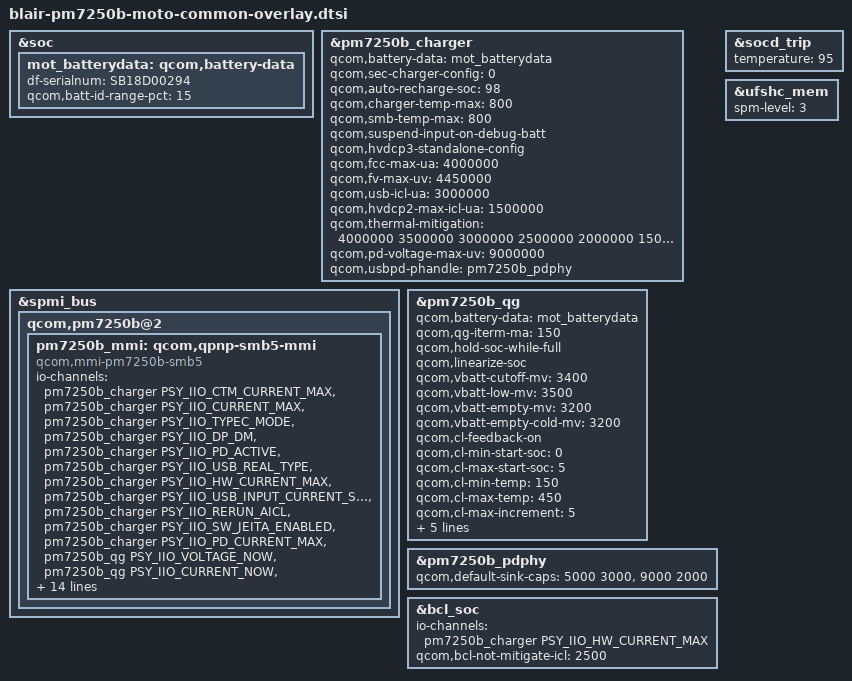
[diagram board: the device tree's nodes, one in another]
/* Copyright (c) 2020, The Linux Foundation. All rights reserved.
 *
 * This program is free software; you can redistribute it and/or modify
 * it under the terms of the GNU General Public License version 2 and
 * only version 2 as published by the Free Software Foundation.
 *
 * This program is distributed in the hope that it will be useful,
 * but WITHOUT ANY WARRANTY; without even the implied warranty of
 * MERCHANTABILITY or FITNESS FOR A PARTICULAR PURPOSE.  See the
 * GNU General Public License for more details.
 */
#include "holi-mtp-pm7250b.dtsi"

&soc{
	mot_batterydata: qcom,battery-data {
		df-serialnum = "SB18D00294";
		qcom,batt-id-range-pct = <15>;
		//#include "qg-batterydata-md50-amperex-5000mah.dtsi"
	};
};

&pm7250b_charger {
	status = "ok";
	qcom,battery-data = <&mot_batterydata>;
	qcom,sec-charger-config = <0>;
	qcom,auto-recharge-soc = <98>;
	qcom,charger-temp-max = <800>;
	qcom,smb-temp-max = <800>;
	qcom,suspend-input-on-debug-batt;
	qcom,hvdcp3-standalone-config;
	qcom,fcc-max-ua = <4000000>;
	qcom,fv-max-uv = <4450000>;
	qcom,usb-icl-ua = <3000000>;
	qcom,hvdcp2-max-icl-ua = <1500000>;
	qcom,thermal-mitigation = <4000000 3500000
			3000000 2500000
			2000000 1500000
			1200000 900000
			600000 300000>;
	qcom,pd-voltage-max-uv = <9000000>;
	qcom,usbpd-phandle = <&pm7250b_pdphy>;
};

&spmi_bus {
	qcom,pm7250b@2 {
		pm7250b_mmi: qcom,qpnp-smb5-mmi {
			status = "ok";
			compatible = "qcom,mmi-pm7250b-smb5";
			#io-channel-cells = <1>;
			io-channels = <&pm7250b_charger PSY_IIO_CTM_CURRENT_MAX>,
				      <&pm7250b_charger PSY_IIO_CURRENT_MAX>,
				      <&pm7250b_charger PSY_IIO_TYPEC_MODE>,
				      <&pm7250b_charger PSY_IIO_DP_DM>,
				      <&pm7250b_charger PSY_IIO_PD_ACTIVE>,
				      <&pm7250b_charger PSY_IIO_USB_REAL_TYPE>,
				      <&pm7250b_charger PSY_IIO_HW_CURRENT_MAX>,
				      <&pm7250b_charger PSY_IIO_USB_INPUT_CURRENT_SETTLED>,
				      <&pm7250b_charger PSY_IIO_RERUN_AICL>,
				      <&pm7250b_charger PSY_IIO_SW_JEITA_ENABLED>,
				      <&pm7250b_charger PSY_IIO_PD_CURRENT_MAX>,
				      <&pm7250b_qg PSY_IIO_VOLTAGE_NOW>,
				      <&pm7250b_qg PSY_IIO_CURRENT_NOW>,
				      <&pm7250b_qg PSY_IIO_TEMP>,
				      <&pm7250b_qg PSY_IIO_CAPACITY>,
				      <&pm7250b_qg PSY_IIO_CHARGE_FULL>,
				      <&pm7250b_qg PSY_IIO_BATT_FULL_CURRENT>,
				      <&pm7250b_qg PSY_IIO_CHARGE_FULL_DESIGN>;
			io-channel-names = "usb_ctm_current_max",
					   "main_current_max",
					   "usb_typec_mode",
					   "battery_dp_dm",
					   "usb_pd_active",
					   "usb_real_type",
					   "usb_hw_current_max",
					   "usb_input_current_settled",
					   "battery_rerun_aicl",
					   "battery_sw_jeita_enabled",
					   "usb_pd_current_max",
					   "voltage_now",
					   "current_now",
					   "temp",
					   "capacity",
					   "charge_full",
					   "batt_full_current",
					   "charge_full_design";
			qcom,enable-charging-limit;
			qcom,upper-limit-capacity = <65>;
			qcom,lower-limit-capacity = <60>;
			qcom,mmi-temp-zones = <0 4200 970 0>,
						<10 4200 2500 970>,
						<15 0 2500 2500>,
						<45 0 4000 4000>,
						<60 4200 2500 0>;
			qcom,iterm-ma = <242>;
			qcom,force-hvdcp-5v;
			qcom,usbpd-phandle = <&pm7250b_pdphy>;
		};
	};
};

&pm7250b_qg {
	status = "ok";
	qcom,battery-data = <&mot_batterydata>;
	qcom,qg-iterm-ma = <150>;
	qcom,hold-soc-while-full;
	qcom,linearize-soc;
	qcom,vbatt-cutoff-mv = <3400>;
	qcom,vbatt-low-mv = <3500>;
	qcom,vbatt-empty-mv = <3200>;
	qcom,vbatt-empty-cold-mv = <3200>;
	qcom,cl-feedback-on;
	qcom,cl-min-start-soc = <0>;
	qcom,cl-max-start-soc = <5>;
	qcom,cl-min-temp = <150>;
	qcom,cl-max-temp = <450>;
	qcom,cl-max-increment = <5>;
	qcom,cl-max-decrement = <10>;
	qcom,cl-min-limit = <200>;
	qcom,cl-max-limit = <30>;
	qcom,s3-entry-ibat-ua = <35000>;
	qcom,s3-exit-ibat-ua = <50000>;
};

&pm7250b_pdphy {
	qcom,default-sink-caps = <5000 3000>, /*5V @ 3A*/
				 <9000 2000>; /*9V @ 2A*/
};

&bcl_soc {
	io-channels = <&pm7250b_charger PSY_IIO_HW_CURRENT_MAX>;
	io-channel-names = "usb_hw_current_max";
	qcom,bcl-not-mitigate-icl = <2500>;
};

&socd_trip {
       temperature = <95>;
};

&ufshc_mem {
	spm-level = <3>;
};
